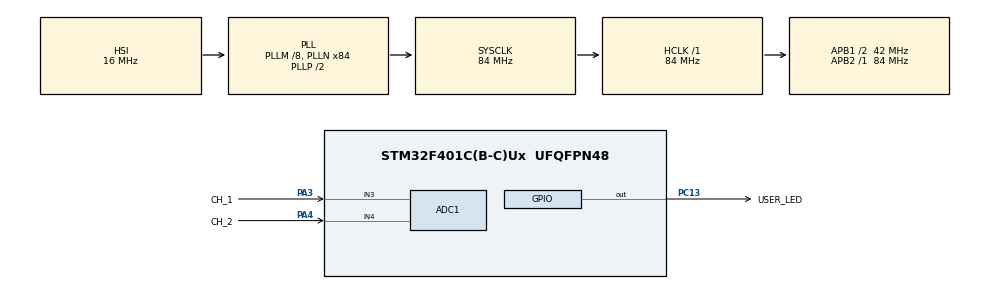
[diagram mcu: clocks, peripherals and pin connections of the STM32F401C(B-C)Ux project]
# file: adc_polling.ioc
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ADC1.Channel-0\#ChannelRegularConversion=ADC_CHANNEL_4
ADC1.Channel-2\#ChannelRegularConversion=ADC_CHANNEL_3
ADC1.NbrOfConversion=2
ADC1.NbrOfConversionFlag=1
ADC1.Rank-0\#ChannelRegularConversion=1
ADC1.Rank-2\#ChannelRegularConversion=2
ADC1.SamplingTime-0\#ChannelRegularConversion=ADC_SAMPLETIME_3CYCLES
ADC1.SamplingTime-2\#ChannelRegularConversion=ADC_SAMPLETIME_3CYCLES
ADC1.master=1
Mcu.Family=STM32F4
Mcu.Name=STM32F401C(B-C)Ux
Mcu.Package=UFQFPN48
NVIC.PriorityGroup=NVIC_PRIORITYGROUP_4
NVIC.TIM1_UP_TIM10_IRQn=true\:2\:0\:true\:false\:true\:true\:true
NVIC.TIM2_IRQn=true\:1\:0\:true\:false\:true\:true\:true
PA13.Mode=Serial_Wire
PA13.Signal=SYS_JTMS-SWDIO
PA14.Mode=Serial_Wire
PA14.Signal=SYS_JTCK-SWCLK
PA3.GPIO_Label=CH_1
PA3.GPIO_Mode=GPIO_MODE_ANALOG
PA3.Signal=ADCx_IN3
PA4.GPIO_Label=CH_2
PA4.Signal=ADCx_IN4
PC13-ANTI_TAMP.GPIO_Label=USER_LED
PC13-ANTI_TAMP.Signal=GPIO_Output
PC14-OSC32_IN.Mode=LSE-External-Oscillator
PC14-OSC32_IN.Signal=RCC_OSC32_IN
PC15-OSC32_OUT.Mode=LSE-External-Oscillator
PC15-OSC32_OUT.Signal=RCC_OSC32_OUT
PH0\ -\ OSC_IN.Mode=HSE-External-Oscillator
PH0\ -\ OSC_IN.Signal=RCC_OSC_IN
PH1\ -\ OSC_OUT.Mode=HSE-External-Oscillator
PH1\ -\ OSC_OUT.Signal=RCC_OSC_OUT
ProjectManager.HeapSize=0x200
ProjectManager.StackSize=0x400
ProjectManager.TargetToolchain=STM32CubeIDE
RCC.48MHZClocksFreq_Value=42000000
RCC.AHBFreq_Value=84000000
RCC.APB1CLKDivider=RCC_HCLK_DIV2
RCC.APB1Freq_Value=42000000
RCC.APB1TimFreq_Value=84000000
RCC.APB2Freq_Value=84000000
RCC.APB2TimFreq_Value=84000000
RCC.CortexFreq_Value=84000000
RCC.HCLKFreq_Value=84000000
RCC.HSE_VALUE=25000000
RCC.HSI_VALUE=16000000
RCC.PLLM=8
RCC.PLLN=84
RCC.SYSCLKFreq_VALUE=84000000
RCC.SYSCLKSource=RCC_SYSCLKSOURCE_PLLCLK
RCC.VCOOutputFreq_Value=168000000
SH.ADCx_IN3.0=ADC1_IN3,IN3
SH.ADCx_IN4.0=ADC1_IN4,IN4
TIM1.AutoReloadPreload=TIM_AUTORELOAD_PRELOAD_DISABLE
TIM1.Period=1999
TIM1.Prescaler=41999
TIM2.Period=399
TIM2.Prescaler=41999
VP_TIM1_VS_ClockSourceINT.Mode=Internal
VP_TIM2_VS_ClockSourceINT.Mode=Internal
board=custom

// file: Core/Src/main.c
/* USER CODE BEGIN Header */
/**
  ******************************************************************************
  * @file           : main.c
  * @brief          : Main program body
  ******************************************************************************
  * @attention
  *
  * Copyright (c) 2022 STMicroelectronics.
  * All rights reserved.
  *
  * This software is licensed under terms that can be found in the LICENSE file
  * in the root directory of this software component.
  * If no LICENSE file comes with this software, it is provided AS-IS.
  *
  ******************************************************************************
  */
/* USER CODE END Header */
#include "main.h"

ADC_HandleTypeDef hadc1;

TIM_HandleTypeDef htim1;
TIM_HandleTypeDef htim2;

/* USER CODE BEGIN PV */
#include "app.h"
/* USER CODE END PV */

void SystemClock_Config(void);
static void MX_GPIO_Init(void);
static void MX_ADC1_Init(void);
static void MX_TIM1_Init(void);
static void MX_TIM2_Init(void);

int main(void)
{

  /* MCU Configuration--------------------------------------------------------*/

  /* Reset of all peripherals, Initializes the Flash interface and the Systick. */
  HAL_Init();

  /* Configure the system clock */
  SystemClock_Config();

  /* Initialize all configured peripherals */
  MX_GPIO_Init();
  MX_ADC1_Init();
  MX_TIM1_Init();
  MX_TIM2_Init();
  /* USER CODE BEGIN 2 */
  // HAL_DBGMCU_EnableDBGSleepMode();
  app_init();
  /* USER CODE END 2 */

  /* Infinite loop */
  while (1)
  {
	  app_loop();
  }
}

void SystemClock_Config(void)
{
  RCC_OscInitTypeDef RCC_OscInitStruct = {0};
  RCC_ClkInitTypeDef RCC_ClkInitStruct = {0};

  /** Configure the main internal regulator output voltage
  */
  __HAL_RCC_PWR_CLK_ENABLE();
  __HAL_PWR_VOLTAGESCALING_CONFIG(PWR_REGULATOR_VOLTAGE_SCALE2);
  /** Initializes the RCC Oscillators according to the specified parameters
  * in the RCC_OscInitTypeDef structure.
  */
  RCC_OscInitStruct.OscillatorType = RCC_OSCILLATORTYPE_HSI;
  RCC_OscInitStruct.HSIState = RCC_HSI_ON;
  RCC_OscInitStruct.HSICalibrationValue = RCC_HSICALIBRATION_DEFAULT;
  RCC_OscInitStruct.PLL.PLLState = RCC_PLL_ON;
  RCC_OscInitStruct.PLL.PLLSource = RCC_PLLSOURCE_HSI;
  RCC_OscInitStruct.PLL.PLLM = 8;
  RCC_OscInitStruct.PLL.PLLN = 84;
  RCC_OscInitStruct.PLL.PLLP = RCC_PLLP_DIV2;
  RCC_OscInitStruct.PLL.PLLQ = 4;
  if (HAL_RCC_OscConfig(&RCC_OscInitStruct) != HAL_OK)
  {
    Error_Handler();
  }
  /** Initializes the CPU, AHB and APB buses clocks
  */
  RCC_ClkInitStruct.ClockType = RCC_CLOCKTYPE_HCLK|RCC_CLOCKTYPE_SYSCLK
                              |RCC_CLOCKTYPE_PCLK1|RCC_CLOCKTYPE_PCLK2;
  RCC_ClkInitStruct.SYSCLKSource = RCC_SYSCLKSOURCE_PLLCLK;
  RCC_ClkInitStruct.AHBCLKDivider = RCC_SYSCLK_DIV1;
  RCC_ClkInitStruct.APB1CLKDivider = RCC_HCLK_DIV2;
  RCC_ClkInitStruct.APB2CLKDivider = RCC_HCLK_DIV1;

  if (HAL_RCC_ClockConfig(&RCC_ClkInitStruct, FLASH_LATENCY_2) != HAL_OK)
  {
    Error_Handler();
  }
}

static void MX_ADC1_Init(void)
{

  ADC_ChannelConfTypeDef sConfig = {0};

  /** Configure the global features of the ADC (Clock, Resolution, Data Alignment and number of conversion)
  */
  hadc1.Instance = ADC1;
  hadc1.Init.ClockPrescaler = ADC_CLOCK_SYNC_PCLK_DIV4;
  hadc1.Init.Resolution = ADC_RESOLUTION_12B;
  hadc1.Init.ScanConvMode = ENABLE;
  hadc1.Init.ContinuousConvMode = DISABLE;
  hadc1.Init.DiscontinuousConvMode = DISABLE;
  hadc1.Init.ExternalTrigConvEdge = ADC_EXTERNALTRIGCONVEDGE_NONE;
  hadc1.Init.ExternalTrigConv = ADC_SOFTWARE_START;
  hadc1.Init.DataAlign = ADC_DATAALIGN_RIGHT;
  hadc1.Init.NbrOfConversion = 2;
  hadc1.Init.DMAContinuousRequests = DISABLE;
  hadc1.Init.EOCSelection = ADC_EOC_SINGLE_CONV;
  if (HAL_ADC_Init(&hadc1) != HAL_OK)
  {
    Error_Handler();
  }
  /** Configure for the selected ADC regular channel its corresponding rank in the sequencer and its sample time.
  */
  sConfig.Channel = ADC_CHANNEL_4;
  sConfig.Rank = 1;
  sConfig.SamplingTime = ADC_SAMPLETIME_3CYCLES;
  if (HAL_ADC_ConfigChannel(&hadc1, &sConfig) != HAL_OK)
  {
    Error_Handler();
  }
  /** Configure for the selected ADC regular channel its corresponding rank in the sequencer and its sample time.
  */
  sConfig.Channel = ADC_CHANNEL_3;
  sConfig.Rank = 2;
  if (HAL_ADC_ConfigChannel(&hadc1, &sConfig) != HAL_OK)
  {
    Error_Handler();
  }

}

static void MX_TIM1_Init(void)
{

  TIM_ClockConfigTypeDef sClockSourceConfig = {0};
  TIM_MasterConfigTypeDef sMasterConfig = {0};

  htim1.Instance = TIM1;
  htim1.Init.Prescaler = 41999;
  htim1.Init.CounterMode = TIM_COUNTERMODE_UP;
  htim1.Init.Period = 1999;
  htim1.Init.ClockDivision = TIM_CLOCKDIVISION_DIV1;
  htim1.Init.RepetitionCounter = 0;
  htim1.Init.AutoReloadPreload = TIM_AUTORELOAD_PRELOAD_DISABLE;
  if (HAL_TIM_Base_Init(&htim1) != HAL_OK)
  {
    Error_Handler();
  }
  sClockSourceConfig.ClockSource = TIM_CLOCKSOURCE_INTERNAL;
  if (HAL_TIM_ConfigClockSource(&htim1, &sClockSourceConfig) != HAL_OK)
  {
    Error_Handler();
  }
  sMasterConfig.MasterOutputTrigger = TIM_TRGO_RESET;
  sMasterConfig.MasterSlaveMode = TIM_MASTERSLAVEMODE_DISABLE;
  if (HAL_TIMEx_MasterConfigSynchronization(&htim1, &sMasterConfig) != HAL_OK)
  {
    Error_Handler();
  }

}

static void MX_TIM2_Init(void)
{

  TIM_ClockConfigTypeDef sClockSourceConfig = {0};
  TIM_MasterConfigTypeDef sMasterConfig = {0};

  htim2.Instance = TIM2;
  htim2.Init.Prescaler = 41999;
  htim2.Init.CounterMode = TIM_COUNTERMODE_UP;
  htim2.Init.Period = 399;
  htim2.Init.ClockDivision = TIM_CLOCKDIVISION_DIV1;
  htim2.Init.AutoReloadPreload = TIM_AUTORELOAD_PRELOAD_DISABLE;
  if (HAL_TIM_Base_Init(&htim2) != HAL_OK)
  {
    Error_Handler();
  }
  sClockSourceConfig.ClockSource = TIM_CLOCKSOURCE_INTERNAL;
  if (HAL_TIM_ConfigClockSource(&htim2, &sClockSourceConfig) != HAL_OK)
  {
    Error_Handler();
  }
  sMasterConfig.MasterOutputTrigger = TIM_TRGO_RESET;
  sMasterConfig.MasterSlaveMode = TIM_MASTERSLAVEMODE_DISABLE;
  if (HAL_TIMEx_MasterConfigSynchronization(&htim2, &sMasterConfig) != HAL_OK)
  {
    Error_Handler();
  }

}

static void MX_GPIO_Init(void)
{
  GPIO_InitTypeDef GPIO_InitStruct = {0};

  /* GPIO Ports Clock Enable */
  __HAL_RCC_GPIOC_CLK_ENABLE();
  __HAL_RCC_GPIOH_CLK_ENABLE();
  __HAL_RCC_GPIOA_CLK_ENABLE();

  /*Configure GPIO pin Output Level */
  HAL_GPIO_WritePin(USER_LED_GPIO_Port, USER_LED_Pin, GPIO_PIN_RESET);

  /*Configure GPIO pin : USER_LED_Pin */
  GPIO_InitStruct.Pin = USER_LED_Pin;
  GPIO_InitStruct.Mode = GPIO_MODE_OUTPUT_PP;
  GPIO_InitStruct.Pull = GPIO_NOPULL;
  GPIO_InitStruct.Speed = GPIO_SPEED_FREQ_LOW;
  HAL_GPIO_Init(USER_LED_GPIO_Port, &GPIO_InitStruct);

}

void Error_Handler(void)
{
  __disable_irq();
  while (1)
  {
  }
}
